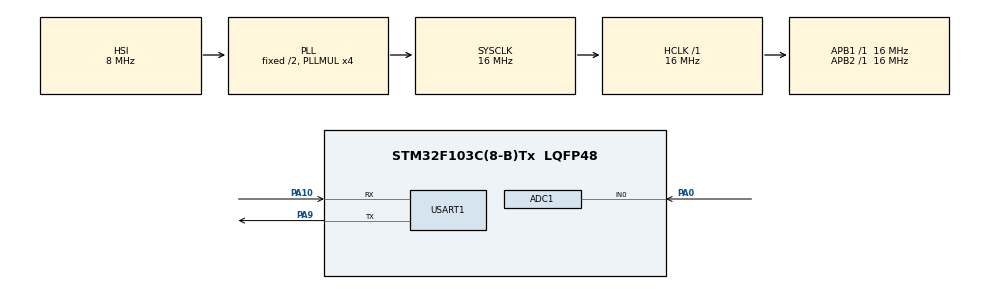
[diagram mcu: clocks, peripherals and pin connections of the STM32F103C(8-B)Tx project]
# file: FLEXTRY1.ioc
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ADC1.Channel-0\#ChannelRegularConversion=ADC_CHANNEL_0
ADC1.ContinuousConvMode=DISABLE
ADC1.NbrOfConversionFlag=1
ADC1.Rank-0\#ChannelRegularConversion=1
ADC1.SamplingTime-0\#ChannelRegularConversion=ADC_SAMPLETIME_13CYCLES_5
ADC1.master=1
Mcu.Family=STM32F1
Mcu.Name=STM32F103C(8-B)Tx
Mcu.Package=LQFP48
NVIC.ADC1_2_IRQn=true\:0\:0\:false\:false\:true\:true\:true\:true
NVIC.PriorityGroup=NVIC_PRIORITYGROUP_4
PA0-WKUP.Signal=ADCx_IN0
PA10.Mode=Asynchronous
PA10.Signal=USART1_RX
PA9.Mode=Asynchronous
PA9.Signal=USART1_TX
PD0-OSC_IN.Mode=HSE-External-Oscillator
PD0-OSC_IN.Signal=RCC_OSC_IN
PD1-OSC_OUT.Mode=HSE-External-Oscillator
PD1-OSC_OUT.Signal=RCC_OSC_OUT
ProjectManager.HeapSize=0x200
ProjectManager.StackSize=0x400
ProjectManager.TargetToolchain=STM32CubeIDE
RCC.AHBFreq_Value=16000000
RCC.APB1Freq_Value=16000000
RCC.APB1TimFreq_Value=16000000
RCC.APB2Freq_Value=16000000
RCC.APB2TimFreq_Value=16000000
RCC.HCLKFreq_Value=16000000
RCC.PLLMUL=RCC_PLL_MUL4
RCC.SYSCLKFreq_VALUE=16000000
RCC.SYSCLKSource=RCC_SYSCLKSOURCE_PLLCLK
RCC.USBFreq_Value=16000000
SH.ADCx_IN0.0=ADC1_IN0,IN0
USART1.VirtualMode=VM_ASYNC
VP_SYS_VS_ND.Mode=No_Debug
board=custom

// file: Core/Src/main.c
/* USER CODE BEGIN Header */
/**
  ******************************************************************************
  * @file           : main.c
  * @brief          : Main program body
  ******************************************************************************
  * @attention
  *
  * Copyright (c) 2023 STMicroelectronics.
  * All rights reserved.
  *
  * This software is licensed under terms that can be found in the LICENSE file
  * in the root directory of this software component.
  * If no LICENSE file comes with this software, it is provided AS-IS.
  *
  ******************************************************************************
  */
/* USER CODE END Header */
#include "main.h"
#include "adc.h"
#include "usart.h"
#include "gpio.h"

/* USER CODE BEGIN Includes */

#include <string.h>
#include <stdlib.h>

/* USER CODE END Includes */

void SystemClock_Config(void);

int main(void)
{
  /* USER CODE BEGIN 1 */
    uint16_t ADC_RES  ;
    char buf[20];
  /* USER CODE END 1 */

  /* MCU Configuration--------------------------------------------------------*/

  /* Reset of all peripherals, Initializes the Flash interface and the Systick. */
  HAL_Init();

  /* Configure the system clock */
  SystemClock_Config();

  /* Initialize all configured peripherals */
  MX_GPIO_Init();
  MX_ADC1_Init();
  MX_USART1_UART_Init();

  /* Infinite loop */
  while (1)
  {

	  HAL_ADC_Start(&hadc1);

      HAL_ADC_PollForConversion(&hadc1, 100);

      ADC_RES = HAL_ADC_GetValue(&hadc1);

      ADC_RES = (char)(uint32_t)ADC_RES ;

      sprintf((char*)buf,"Value: %hu \r\n",ADC_RES);
      HAL_UART_Transmit(&huart1, buf, strlen((char*)buf),HAL_MAX_DELAY);

//      if( ADC_RES < 25){
//          sprintf((char*)buf," %hu \r\n",ADC_RES);
//          HAL_UART_Transmit(&huart1, buf, strlen((char*)buf),HAL_MAX_DELAY);
//      }else{
//          sprintf((char*)buf," %hu \r\n",ADC_RES);
//          HAL_UART_Transmit(&huart1, buf, strlen((char*)buf),HAL_MAX_DELAY);
//      }
  }
}

void SystemClock_Config(void)
{
  RCC_OscInitTypeDef RCC_OscInitStruct = {0};
  RCC_ClkInitTypeDef RCC_ClkInitStruct = {0};
  RCC_PeriphCLKInitTypeDef PeriphClkInit = {0};

  /** Initializes the RCC Oscillators according to the specified parameters
  * in the RCC_OscInitTypeDef structure.
  */
  RCC_OscInitStruct.OscillatorType = RCC_OSCILLATORTYPE_HSI;
  RCC_OscInitStruct.HSIState = RCC_HSI_ON;
  RCC_OscInitStruct.HSICalibrationValue = RCC_HSICALIBRATION_DEFAULT;
  RCC_OscInitStruct.PLL.PLLState = RCC_PLL_ON;
  RCC_OscInitStruct.PLL.PLLSource = RCC_PLLSOURCE_HSI_DIV2;
  RCC_OscInitStruct.PLL.PLLMUL = RCC_PLL_MUL4;
  if (HAL_RCC_OscConfig(&RCC_OscInitStruct) != HAL_OK)
  {
    Error_Handler();
  }

  /** Initializes the CPU, AHB and APB buses clocks
  */
  RCC_ClkInitStruct.ClockType = RCC_CLOCKTYPE_HCLK|RCC_CLOCKTYPE_SYSCLK
                              |RCC_CLOCKTYPE_PCLK1|RCC_CLOCKTYPE_PCLK2;
  RCC_ClkInitStruct.SYSCLKSource = RCC_SYSCLKSOURCE_PLLCLK;
  RCC_ClkInitStruct.AHBCLKDivider = RCC_SYSCLK_DIV1;
  RCC_ClkInitStruct.APB1CLKDivider = RCC_HCLK_DIV1;
  RCC_ClkInitStruct.APB2CLKDivider = RCC_HCLK_DIV1;

  if (HAL_RCC_ClockConfig(&RCC_ClkInitStruct, FLASH_LATENCY_0) != HAL_OK)
  {
    Error_Handler();
  }
  PeriphClkInit.PeriphClockSelection = RCC_PERIPHCLK_ADC;
  PeriphClkInit.AdcClockSelection = RCC_ADCPCLK2_DIV2;
  if (HAL_RCCEx_PeriphCLKConfig(&PeriphClkInit) != HAL_OK)
  {
    Error_Handler();
  }
}

void Error_Handler(void)
{
  __disable_irq();
  while (1)
  {
  }
}
